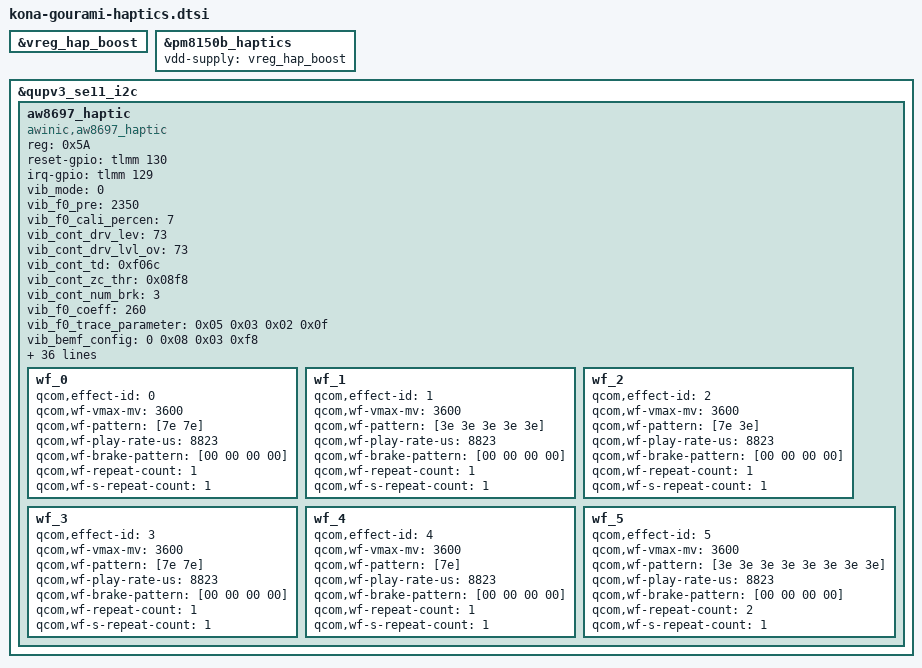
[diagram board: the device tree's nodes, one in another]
// SPDX-License-Identifier: GPL-2.0
/* Copyright (c) 2022, The Linux Foundation. All rights reserved.
 *
 * This program is free software; you can redistribute it and/or modify
 * it under the terms of the GNU General Public License version 2 and
 * only version 2 as published by the Free Software Foundation.
 *
 * This program is distributed in the hope that it will be useful,
 * but WITHOUT ANY WARRANTY; without even the implied warranty of
 * MERCHANTABILITY or FITNESS FOR A PARTICULAR PURPOSE.  See the
 * GNU General Public License for more details.
 */

&vreg_hap_boost {
	status = "ok";
};

&pm8150b_haptics {
	vdd-supply = <&vreg_hap_boost>;
};

&qupv3_se11_i2c {
	status = "ok";

	aw8697_haptic: aw8697_haptic {
		status = "ok";
		compatible = "awinic,aw8697_haptic";
		reg = <0x5A>;
		reset-gpio = <&tlmm 130 0>;
		irq-gpio = <&tlmm 129 0>;
		vib_mode = < 0 >;   /*mode:   RAM mode->0; CONT mode -> 1*/
		vib_f0_pre = < 2350 >;
		vib_f0_cali_percen = < 7 >;
		vib_cont_drv_lev = < 73 >;
		vib_cont_drv_lvl_ov = < 73 >;
		vib_cont_td = < 0xf06c >;
		vib_cont_zc_thr = < 0x08f8 >;  /*hq 0x08F8 */
		vib_cont_num_brk = < 3 >;
		vib_f0_coeff = < 260 >; /*Don't modify it    2.604167*/
		vib_f0_trace_parameter = < 0x05 0x03 0x02 0x0f >;
		vib_bemf_config = < 0 0x08 0x03 0xf8 >;
		vib_sw_brake = < 0x2c >;
		vib_tset = < 0x12 >;
		vib_r_spare = < 0x68 >;
		vib_bstdbg = < 0x30 0xeb 0xd4 0 0 0 >;
		vib_effect_id_boundary = < 10 >;
		vib_effect_max = < 193 >;
		vib_trig_config = < 0 1 0 1 2
						0 1 0 1 2
						0 1 0 1 2 >;
		vib_bst_vol_default = < 0x11 >;
		vib_bst_vol_ram = < 0x11 >;
		vib_bst_vol_rtp = < 0x11 >;
		vib_cont_drv1_lvl = < 0x7F >;
		vib_cont_drv2_lvl = < 0x36 >;
		vib_cont_drv1_time = < 0x04 >;
		vib_cont_drv2_time = < 0x14 >;
		vib_cont_drv_width = < 0x6A >;
		vib_cont_wait_num = < 0x06 >;
		vib_cont_bst_brk_gain = < 0x05 >;
		vib_cont_brk_gain = < 0x08 >;
		vib_cont_tset = < 0x06 >;
		vib_cont_bemf_set = < 0x02 >;
		vib_d2s_gain = < 0x04 >;
		vib_cont_brk_time = < 0x00 >;
		vib_cont_track_margin = < 0x12 >;
		vib_bstcfg = < 0x20 0x24 0x96 0x40 0x11 >;
		vib_prctmode = < 0x2D 0x3E 0x3F >;
		vib_sine_array = < 0x05 0xB2 0xFF 0xEF >;
		vib_trig_config_9xx = < 1 0 1 1 1 2 0 0
					1 0 0 1 0 2 0 0
					1 0 0 1 0 2 0 0 >;
		vib_bst_vol_default_9xx = < 0x0B >;
		vib_bst_vol_ram_9xx = < 0x0B >;
		vib_bst_vol_rtp_9xx = < 0x0B >;
		vib_rtp_time = < 20 20 20 20 20 20 20 20 20000 15000
				 15000 20000 25000 15000 30000 25000 20000 20000 20000 20000
				 20000 20000 20000 20000 20000 20000 20000 20000 20000 20000
				 20000 20000 20000 20000 20000 20000 20000 20000 20000 20000
				 20000 20000 20000 20000 20000 20000 20000 20000 20000 20000
				 20000 20000 20000 20000 20000 20000 20000 20000 20000 20000
				 20000 20000 20000 20000 20000 20000 20000 20000 20000 20000
				 20000 20000 20000 20000 20000 20000 20000 20000 20000 20000
				 20000 20000 20000 20000 20000 20000 20000 20000 20000 20000
				 20000 20000 20000 20000 20000 20000 20000 20000 20000 20000
				 20000 20000 20000 20000 20000 20000 20000 20000 20000 20000
				 20000 20000 20000 20000 20000 20000 20000 20000 20000 20000
				 20000 20000 20000 20000 20000 20000 20000 20000 20000 20000
				 20000 20000 20000 20000 20000 20000 20000 20000 20000 20000
				 20000 20000 20000 20000 20000 20000 20000 20000 20000 20000
				 20000 20000 20000 20000 20000 20000 20000 20000 20000 20000
				 20000 20000 20000 20000 20000 20000 20000 20000 20000 20000
				 20000 20000 20000 20000 20000 >;
		pinctrl-names = "aw8697_reset_reset", 
						"aw8697_reset_active",
						"aw8697_interrupt_active";
		pinctrl-0 = <&aw8697_gpio_reset>;
		pinctrl-1 = <&aw8697_gpio_reset_output_high>;
		pinctrl-2 = <&aw8697_gpio_int>;
		wf_0 {
			/* CLICK */
			qcom,effect-id = <0>;
			qcom,wf-vmax-mv = <3600>;
			qcom,wf-pattern = [7e 7e];
			qcom,wf-play-rate-us = <8823>;
			qcom,wf-brake-pattern = [00 00 00 00];
			qcom,wf-repeat-count = <1>;
			qcom,wf-s-repeat-count = <1>;
		};

		wf_1 {
			/* DOUBLE CLICK */
			qcom,effect-id = <1>;
			qcom,wf-vmax-mv = <3600>;
			qcom,wf-pattern = [3e 3e 3e 3e 3e];
			qcom,wf-play-rate-us = <8823>;
			qcom,wf-brake-pattern = [00 00 00 00];
			qcom,wf-repeat-count = <1>;
			qcom,wf-s-repeat-count = <1>;
		};

		wf_2 {
			/* TICK */
			qcom,effect-id = <2>;
			qcom,wf-vmax-mv = <3600>;
			qcom,wf-pattern = [7e 3e];
			qcom,wf-play-rate-us = <8823>;
			qcom,wf-brake-pattern = [00 00 00 00];
			qcom,wf-repeat-count = <1>;
			qcom,wf-s-repeat-count = <1>;
		};

		wf_3 {
			/* THUD */
			qcom,effect-id = <3>;
			qcom,wf-vmax-mv = <3600>;
			qcom,wf-pattern = [7e 7e];
			qcom,wf-play-rate-us = <8823>;
			qcom,wf-brake-pattern = [00 00 00 00];
			qcom,wf-repeat-count = <1>;
			qcom,wf-s-repeat-count = <1>;
		};

		wf_4 {
			/* POP */
			qcom,effect-id = <4>;
			qcom,wf-vmax-mv = <3600>;
			qcom,wf-pattern = [7e];
			qcom,wf-play-rate-us = <8823>;
			qcom,wf-brake-pattern = [00 00 00 00];
			qcom,wf-repeat-count = <1>;
			qcom,wf-s-repeat-count = <1>;
		};

		wf_5 {
			/* HEAVY CLICK */
			qcom,effect-id = <5>;
			qcom,wf-vmax-mv = <3600>;
			qcom,wf-pattern = [3e 3e 3e 3e 3e 3e 3e 3e];
			qcom,wf-play-rate-us = <8823>;
			qcom,wf-brake-pattern = [00 00 00 00];
			qcom,wf-repeat-count = <2>;
			qcom,wf-s-repeat-count = <1>;
		};
	};
};
